# GPU_WRAPPER register map
Vendor: Texas Instruments
Peripheral module from a debugger description file (folder omap5430_ES2_PUBLIC).
Registers are 32-bit, access per field, reset 0x0 unless marked. A register's access mark holds for its fields unless they carry their own. Offsets are as the file gives them; lines under a group give offsets from that group; [hi:lo] are bit positions; {n}, {i} and the like mark numbered series; 'fields as' and 'values as' point back to an identical list; <NAME> marks a mode.

## GPU_WRAPPER
0x00 REVISION ro reset not defined
  [31:0] REVISIONID — Revision value
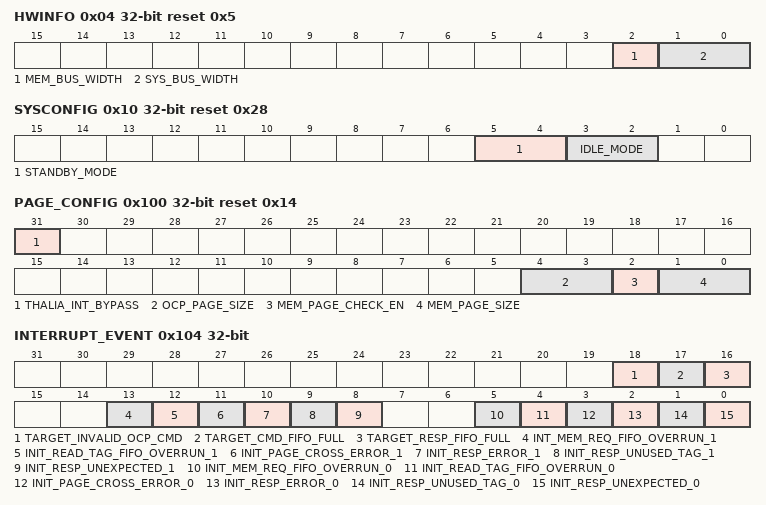
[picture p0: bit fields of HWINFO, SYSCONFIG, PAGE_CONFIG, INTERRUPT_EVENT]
0x04 HWINFO ro reset 0x5 — Hardware implementation information
  [2] MEM_BUS_WIDTH — Memory bus width Read 0x0: 64 bits Read 0x1: 128 bits
  [1:0] SYS_BUS_WIDTH — System bus width Read 0x0: 32 bits Read 0x1: 64 bits Read 0x2: 128 bits Read 0x3: Reserved
0x10 SYSCONFIG reset 0x28 — System configuration register
  [5:4] STANDBY_MODE rw — Clock standby mode: 0x0: Force-standby 0x1: No-standby 0x2: Smart-standby 0x3: Reserved
  [3:2] IDLE_MODE rw — Clock idle mode: 0x0: Force-standby 0x1: No-standby 0x2: Smart-standby 0x3: Reserved
0x24 IRQSTATUS_RAW_0 — Raw IRQ 0 status
  [0] INIT_MINTERRUPT_RAW rw — Interrupt 0 raw event: Write 0x0: No action Write 0x1: Set event (used for debug) Read 0x0: No event pending Read 0x1: Event pending
0x28 IRQSTATUS_RAW_1 — Raw IRQ 1 status. Slave port interrupt.
  [0] TARGET_SINTERRUPT_RAW rw — Interrupt 1 raw event: Write 0x0: No action Write 0x1: Set event (used for debug) Read 0x0: No event pending Read 0x1: Event pending
0x2C IRQSTATUS_RAW_2 — Raw IRQ 2 status. Core interrupt.
  [0] THALIA_IRQ_RAW rw — Interrupt 0 raw event: Write 0x0: No action Write 0x1: Set event (used for debug) Read 0x0: No event pending Read 0x1: Event pending
0x30 IRQSTATUS_0 — Interrupt 0 status event. Master port interrupt.
  [0] INIT_MINTERRUPT_STATUS rw — Interrupt 0 raw event: Write 0x0: No action Write 0x1: Clear event Read 0x0: No event pending Read 0x1: Event pending and interrupt enabled
0x34 IRQSTATUS_1 — Interrupt 1 - slave port status event
  [0] TARGET_SINTERRUPT_STATUS rw — Interrupt 0 raw event: Write 0x0: No action Write 0x1: Clear event Read 0x0: No event pending Read 0x1: Event pending and interrupt enabled
0x38 IRQSTATUS_2 — Interrupt 2 - Core status event
  [0] THALIA_IRQ_STATUS rw — Interrupt 0 raw event: Write 0x0: No action Write 0x1: Clear event Read 0x0: No event pending Read 0x1: Event pending and interrupt enabled
0x3C IRQENABLE_SET_0 — Enable Interrupt 0 - Master port.
  [0] INIT_MINTERRUPT_ENABLE rw — To enable interrupt: Write 0x0: No action Write 0x1: Enable interrupt Read 0x0: Interrupt is disabled Read 0x1: Interrupt is enabled
0x40 IRQENABLE_SET_1 — Enable Interrupt 1. Core interrupt.
  [0] TARGET_SINTERRUPT_ENABLE rw — To enable interrupt: Write 0x0: No action Write 0x1: Enable interrupt Read 0x0: Interrupt is disabled Read 0x1: Interrupt is enabled
0x44 IRQENABLE_SET_2 — Enable Interrupt 2. Core interrupt.
  [0] THALIA_IRQ_ENABLE rw — To enable interrupt: Write 0x0: No action Write 0x1: Enable interrupt Read 0x0: Interrupt is disabled Read 0x1: Interrupt is enabled
0x48 IRQENABLE_CLR_0 — Disable Interrupt 0 - Master port.
  [0] INIT_MINTERRUPT_DISABLE rw — To disable interrupt: Write 0x0: No action Write 0x1: Disable interrupt Read 0x0: Interrupt is disabled Read 0x1: Interrupt is enabled
0x4C IRQENABLE_CLR_1 — Disable Interrupt 2 - Core interrupt.
  [0] TARGET_SINTERRUPT_DISABLE rw — To disable interrupt: Write 0x0: No action Write 0x1: Disable interrupt Read 0x0: Interrupt is disabled Read 0x1: Interrupt is enabled
0x50 IRQENABLE_CLR_2 — Disable Interrupt 2 - Core interrupt.
  [0] THALIA_IRQ_DISABLE rw — To disable interrupt: Write 0x0: No action Write 0x1: Disable interrupt Read 0x0: Interrupt is disabled Read 0x1: Interrupt is enabled
0x100 PAGE_CONFIG reset 0x14 — Configure memory pages.
  [31] THALIA_INT_BYPASS rw — Bypass OCP IPG interrupt logic 0x0: Do not bypass 0x1 Bypass core interrupt to I/O pin; that is, disregard the interrupt enable setting in the IPG register.
  [4:3] OCP_PAGE_SIZE rw — Defines the page size on OCP memory interface: 0x0: 4 KiB 0x1: 2 KiB 0x2: 1 KiB 0x3: 512B
  [2] MEM_PAGE_CHECK_EN rw — To enable page boundary checking: 0x0: Disabled 0x1: Enabled
  [1:0] MEM_PAGE_SIZE rw — Defines the page size on internal memory interface: 0x0: 4 KiB 0x1: 2 KiB 0x2: 1 KiB 0x3: 512B
0x104 INTERRUPT_EVENT — Interrupt events
  [18] TARGET_INVALID_OCP_CMD rw — Invalid command from OCP: Write 0x0: Clear the event Write 0x1: Set the event and interrupt if enabled (debug only) Read 0x0: No event pending Read 0x1: Event pending
  [17] TARGET_CMD_FIFO_FULL rw — Command FIFO full: Write 0x0: Clear the event. Write 0x1: Set the event and interrupt if enabled (debug only). Read 0x0: No event pending Read 0x1: Event pending
  [16] TARGET_RESP_FIFO_FULL rw — Response FIFO full: Write 0x0: Clear the event. Write 0x1: Set the event and interrupt if enabled (debug only). Read 0x0: No event pending Read 0x1: Event pending
  [13] INT_MEM_REQ_FIFO_OVERRUN_1 rw — Memory request FIFO overrun: Write 0x0: Clear the event. Write 0x1: Set the event and interrupt if enabled (debug only). Read 0x0: No event pending Read 0x1: Event pending
  [12] INIT_READ_TAG_FIFO_OVERRUN_1 rw — Read tag FIFO overrun: Write 0x0: Clear the event. Write 0x1: Set the event and interrupt if enabled (debug only). Read 0x0: No event pending Read 0x1: Event pending
  [11] INIT_PAGE_CROSS_ERROR_1 rw — Memory page had been crossed during a burst: Write 0x0: Clear the event. Write 0x1: Set the event and interrupt if enabled (debug only). Read 0x0: No event pending Read 0x1: Event pending
  [10] INIT_RESP_ERROR_1 rw — Receiving error response: Write 0x0: Clear the event. Write 0x1: Set the event and interrupt if enabled (debug only). Read 0x0: No event pending Read 0x1: Event pending
  [9] INIT_RESP_UNUSED_TAG_1 rw — Receiving response on an unused OCP TAG: Write 0x0: Clear the event Write 0x1: Set the event and interrupt if enabled (debug only) Read 0x0: No event pending Read 0x1: Event pending
  [8] INIT_RESP_UNEXPECTED_1 rw — Receiving response when not expected: Write 0x0: Clear the event. Write 0x1: Set the event and interrupt if enabled (debug only). Read 0x0: No event pending Read 0x1: Event pending
  [5] INIT_MEM_REQ_FIFO_OVERRUN_0 rw — Memory request FIFO overrun; Write 0x0: Clear the event. Write 0x1: Set the event and interrupt if enabled (debug only). Read 0x0: No event pending Read 0x1: Event pending
  [4] INIT_READ_TAG_FIFO_OVERRUN_0 rw — Read tag FIFO overrun: Write 0x0: Clear the event. Write 0x1: Set the event and interrupt if enabled (debug only). Read 0x0: No event pending Read 0x1: Event pending
  [3] INIT_PAGE_CROSS_ERROR_0 rw — Memory page had been crossed during a burst. Write 0x0: Clear the event. Write 0x1: Set the event and interrupt if enabled (debug only). Read 0x0: No event pending Read 0x1: Event pending
  [2] INIT_RESP_ERROR_0 rw — Receiving error response: Write 0x0: Clear the event. Write 0x1: Set the event and interrupt if enabled (debug only). Read 0x0: No event pending Read 0x1: Event pending
  [1] INIT_RESP_UNUSED_TAG_0 rw — Receiving response on an unused OCP TAG: Write 0x0: Clear the event. Write 0x1: Set the event and interrupt if enabled (debug only). Read 0x0: No event pending Read 0x1: Event pending
  [0] INIT_RESP_UNEXPECTED_0 rw — Receiving response when not expected: Write 0x0: Clear the event. Write 0x1: Set the event and interrupt if enabled (debug only). Read 0x0: No event pending Read 0x1: Event pending
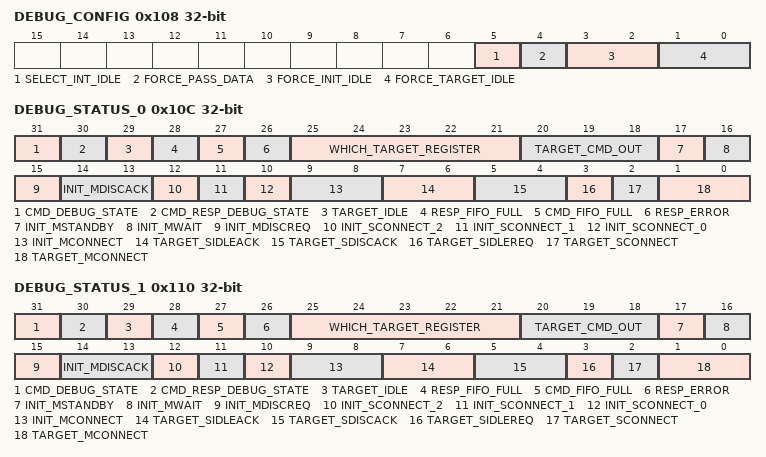
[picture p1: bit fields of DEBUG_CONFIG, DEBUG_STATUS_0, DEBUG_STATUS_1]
0x108 DEBUG_CONFIG — Configuration of debug modes
  [5] SELECT_INT_IDLE rw — To select which idle the disconnect protocol should act on: 0x0: Whole SGX idle 0x1: OCP initiator idle
  [4] FORCE_PASS_DATA rw — Forces the initiator to pass data independent of disconnect protocol: 0x0: Do not force, normal operation 0x1: Never fence request to OCP
  [3:2] FORCE_INIT_IDLE rw — Forces initiator idle: 0x0, 0x3: Do not force, normal operation 0x1: Always idle 0x2: Never idle
  [1:0] FORCE_TARGET_IDLE rw — Forces target idle: 0x0, 0x3: Do not force, normal operation 0x1: Always idle 0x2: Never idle
0x10C DEBUG_STATUS_0 ro — Port0 debug status register
  [31] CMD_DEBUG_STATE — Target command state-machine: 0x0: IDLE 0x1: Accept command
  [30] CMD_RESP_DEBUG_STATE — Target response state-machine: 0x0: Send accept 0x1: Wait accept
  [29] TARGET_IDLE
  [28] RESP_FIFO_FULL — Target response FIFO full
  [27] CMD_FIFO_FULL — Target command FIFO full
  [26] RESP_ERROR — Respond to OCP with error, which could be caused by either address misalignment or invalid byte enable.
  [25:21] WHICH_TARGET_REGISTER — Indicates which OCP target registers to read
  [20:18] TARGET_CMD_OUT — Command received from OCP: 0x0: CMD_WRSYS 0x1: CMD_RDSYS 0x2: CMD_WR_ERROR 0x3: CMD_RD_ERROR 0x4: CMD_CHK_WRADDR_PAGE (not used) 0x5: CMD_CHK_RDADDR_PAGE (not used) 0x6: CMD_TARGET_REG_WRITE 0x7: CMD_TARGET_REG_READ
  [17] INIT_MSTANDBY — Status of init_MStandby signal
  [16] INIT_MWAIT — Status of init_MWait signal
  [15] INIT_MDISCREQ — Request to disconnect from OCP interface
  [14:13] INIT_MDISCACK — Disconnect status of the OCP interface: 0x0: FUNCT 0x1: TRANS 0x2: Reserved 0x3: IDLE
  [12] INIT_SCONNECT_2 — Defines whether to wait in M_WAIT state for MConnect FSM: 0x0: Skip M_WAIT state 0x1: Wait in M_WAIT state
  [11] INIT_SCONNECT_1 — Defines the busy-ness state of the slave: 0x0: Slave is drained 0x1: Slave is loaded
  [10] INIT_SCONNECT_0 — Disconnect from slave: 0x0: Disconnect request from slave 0x1: Connect request from slave
  [9:8] INIT_MCONNECT — Initiator MConnect state: 0x0: M_OFF 0x1: M_WAIT 0x2: M_DISC 0x3: M_CON
  [7:6] TARGET_SIDLEACK — Acknowledge the SIdleAck state-machine: 0x0: FUNCT 0x1: SLEEP TRANS 0x2: Reserved 0x3: IDLE
  [5:4] TARGET_SDISCACK — Acknowledge the SDiscAck state-machine: 0x0: FUNCT 0x1: TRANS 0x2: Reserved 0x3: IDLE
  [3] TARGET_SIDLEREQ — Request the target to go idle: 0 Do not go idle, or go active 1 Go idle
  [2] TARGET_SCONNECT — Target SConnect bit 0 state: 0x0: Disconnect interface 0x1: Connect OCP interface
  [1:0] TARGET_MCONNECT — Target MConnect state: 0x0: M_OFF 0x1: M_WAIT 0x2: M_DISC 0x3: M_CON
0x110 DEBUG_STATUS_1 ro — Port1 debug status register
  [31] CMD_DEBUG_STATE — Target command state-machine: 0x0: IDLE 0x1: Accept command
  [30] CMD_RESP_DEBUG_STATE — Target response state-machine: 0x0: Send accept 0x1: Wait accept
  [29] TARGET_IDLE
  [28] RESP_FIFO_FULL — Target response FIFO full
  [27] CMD_FIFO_FULL — Target command FIFO full
  [26] RESP_ERROR — Respond to OCP with error, which could be caused by either address misalignment or invalid byte enable.
  [25:21] WHICH_TARGET_REGISTER — Indicates which OCP target registers to read
  [20:18] TARGET_CMD_OUT — Command received from OCP: 0x0: CMD_WRSYS 0x1: CMD_RDSYS 0x2: CMD_WR_ERROR 0x3: CMD_RD_ERROR 0x4: CMD_CHK_WRADDR_PAGE (not used) 0x5: CMD_CHK_RDADDR_PAGE (not used) 0x6: CMD_TARGET_REG_WRITE 0x7: CMD_TARGET_REG_READ
  [17] INIT_MSTANDBY — Status of init_MStandby signal
  [16] INIT_MWAIT — Status of init_MWait signal
  [15] INIT_MDISCREQ — Request to disconnect from OCP interface
  [14:13] INIT_MDISCACK — Disconnect status of the OCP interface: 0x0: FUNCT 0x1: SLEEP TRANS 0x2: Reserved 0x3: IDLE
  [12] INIT_SCONNECT_2 — Defines whether to wait in M_WAIT state for MConnect FSM: 0x0: Skip M_WAIT state. 0x1: Wait in M_WAIT state.
  [11] INIT_SCONNECT_1 — Defines the busy-ness state of the slave: 0x0: Slave is drained. 0x1: Slave is loaded.
  [10] INIT_SCONNECT_0 — Disconnect from slave: 0x0: Disconnect request from slave 0x1: Connect request from slave
  [9:8] INIT_MCONNECT — Initiator MConnect state: 0x0: M_OFF 0x1: M_WAIT 0x2: M_DISC 0x3: M_CON
  [7:6] TARGET_SIDLEACK — Acknowledge the SIdleAck state-machine: 0x0: FUNCT 0x1: SLEEP TRANS 0x2: Reserved 0x3: IDLE
  [5:4] TARGET_SDISCACK — Acknowledge the SDiscAck state-machine: 0x0: FUNCT 0x1: TRANS 0x2: Reserved 0x3: IDLE
  [3] TARGET_SIDLEREQ — Request the target to go idle: 0x0: Do not go idle, or go active 0x1: Go idle
  [2] TARGET_SCONNECT — Target SConnect bit 0 state: 0x0: Disconnect interface 0x1: Connect OCP interface
  [1:0] TARGET_MCONNECT — Target MConnect state: 0x0: M_OFF 0x1: M_WAIT 0x2: M_DISC 0x3: M_CON
